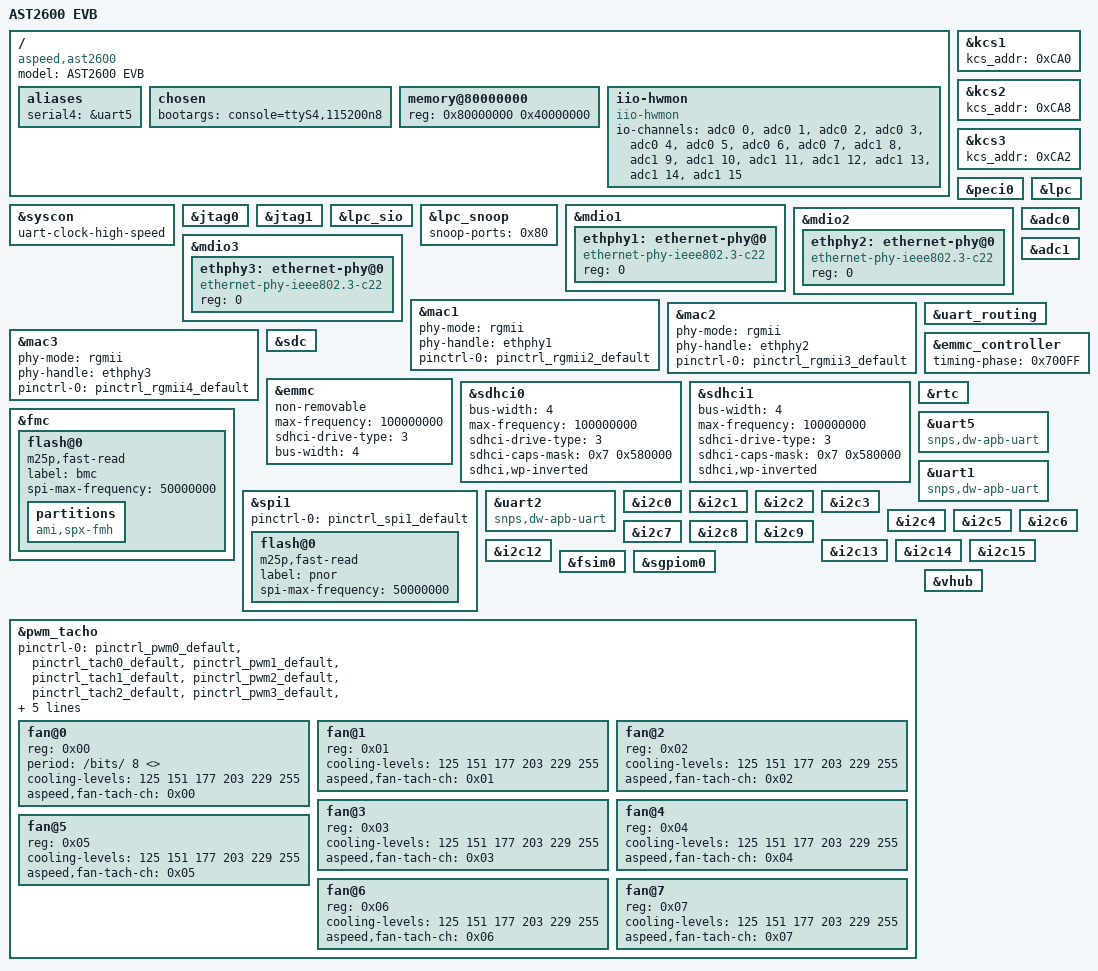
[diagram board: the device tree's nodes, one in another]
// SPDX-License-Identifier: GPL-2.0-or-later
// Copyright 2019 IBM Corp.

/dts-v1/;

#include "aspeed-g6.dtsi"
#include <dt-bindings/gpio/aspeed-gpio.h>
#include <dt-bindings/i2c/i2c.h>

/ {
	model = "AST2600 EVB";
	compatible = "aspeed,ast2600";

	aliases {
		serial4 = &uart5;
	};

	chosen {
		bootargs = "console=ttyS4,115200n8";
	};

	memory@80000000 {
		device_type = "memory";
		reg = <0x80000000 0x40000000>;
	};

    iio-hwmon {
        compatible = "iio-hwmon";
        io-channels = <&adc0 0>, <&adc0 1>, <&adc0 2>, <&adc0 3>,
                        <&adc0 4>, <&adc0 5>, <&adc0 6>, <&adc0 7>,
                        <&adc1 8>, <&adc1 9>, <&adc1 10>, <&adc1 11>,
                        <&adc1 12>, <&adc1 13>, <&adc1 14>, <&adc1 15>;
    };

};

&syscon {
        uart-clock-high-speed;
        status = "okay";
};

&kcs1 {
        kcs_addr = <0xCA0>;
        status = "okay";
};

&kcs2 {
        kcs_addr = <0xCA8>;
        status = "okay";
};

&kcs3 {
        kcs_addr = <0xCA2>;
        status = "okay";
};

&peci0 {
    status = "okay";
};

&lpc {
    status = "okay";
};

&jtag0 {
        status = "okay";
};

&jtag1 {
        status = "okay";
};

&lpc_sio {
        status = "okay";
};

&lpc_snoop {
        snoop-ports = <0x80>;
        status = "okay";
};

&mdio1 {
	status = "okay";

	ethphy1: ethernet-phy@0 {
		compatible = "ethernet-phy-ieee802.3-c22";
		reg = <0>;
	};
};

&mdio2 {
	status = "okay";

	ethphy2: ethernet-phy@0 {
		compatible = "ethernet-phy-ieee802.3-c22";
		reg = <0>;
	};
};

&mdio3 {
	status = "okay";

	ethphy3: ethernet-phy@0 {
		compatible = "ethernet-phy-ieee802.3-c22";
		reg = <0>;
	};
};

&mac1 {
	status = "okay";

	phy-mode = "rgmii";
	phy-handle = <&ethphy1>;

	pinctrl-names = "default";
	pinctrl-0 = <&pinctrl_rgmii2_default>;
};

&mac2 {
	status = "okay";

	phy-mode = "rgmii";
	phy-handle = <&ethphy2>;

	pinctrl-names = "default";
	pinctrl-0 = <&pinctrl_rgmii3_default>;
};

&mac3 {
	status = "okay";

	phy-mode = "rgmii";
	phy-handle = <&ethphy3>;

	pinctrl-names = "default";
	pinctrl-0 = <&pinctrl_rgmii4_default>;
};

&adc0 {
        status = "okay";
};

&adc1 {
        status = "okay";
};

&uart_routing {
        status = "okay";
};

&sdc {
	status = "okay";	
};

&emmc_controller {
	status = "okay";
	timing-phase = <0x700FF>;
};

&emmc {
    status = "okay";
    non-removable;
    max-frequency = <100000000>;
    sdhci-drive-type = /bits/ 8 <3>;
#if 1
    bus-width = <4>;
#else
    bus-width = <8>;
    pinctrl-0 = <&pinctrl_emmc_default
            &pinctrl_emmcg8_default>;
#endif

};

&sdhci0 {
    status = "okay";
    bus-width = <4>;
    max-frequency = <100000000>;
    sdhci-drive-type = /bits/ 8 <3>;
    /* SDR104/DDR50/SDR50 bits in CAPA2 is not supported */
    sdhci-caps-mask = <0x7 0x580000>;
    sdhci,wp-inverted;
};

&sdhci1 {
    status = "okay";
    bus-width = <4>;
    max-frequency = <100000000>;
    sdhci-drive-type = /bits/ 8 <3>;
    sdhci-caps-mask = <0x7 0x580000>;
    sdhci,wp-inverted;
};

&rtc {
	status = "okay";
};

&fmc {
	status = "okay";
	flash@0 {
		status = "okay";
		m25p,fast-read;
		label = "bmc";
		spi-max-frequency = <50000000>;
        partitions {
            compatible = "ami,spx-fmh";
        };
	};
};

&spi1 {
	status = "okay";
	pinctrl-names = "default";
	pinctrl-0 = <&pinctrl_spi1_default>;

	flash@0 {
		status = "okay";
		m25p,fast-read;
		label = "pnor";
		spi-max-frequency = <50000000>;
	};
};

&uart5 {
	// Workaround for A0
	compatible = "snps,dw-apb-uart";
};

&uart1 {
	// Workaround for A0
	compatible = "snps,dw-apb-uart";
	status = "okay";
};

&uart2 {
	// Workaround for A0
	compatible = "snps,dw-apb-uart";
	status = "okay";
};

&i2c0 {
	status = "okay";
};

&i2c1 {
	status = "okay";
};

&i2c2 {
	status = "okay";
};

&i2c3 {
	status = "okay";
};

&i2c4 {
	status = "okay";
};

&i2c5 {
	status = "okay";
};

&i2c6 {
	status = "okay";
};

&i2c7 {
	status = "okay";
};

&i2c8 {
	status = "okay";
};

&i2c9 {
	status = "okay";
};

&i2c12 {
	status = "okay";
};

&i2c13 {
	status = "okay";
};

&i2c14 {
	status = "okay";
};

&i2c15 {
	status = "okay";
};

&fsim0 {
	status = "okay";
};
&sgpiom0 {
        status = "okay";
};

&pwm_tacho {
        status = "okay";
        pinctrl-names = "default";
        pinctrl-0 = <&pinctrl_pwm0_default &pinctrl_tach0_default
                        &pinctrl_pwm1_default &pinctrl_tach1_default
                        &pinctrl_pwm2_default &pinctrl_tach2_default
                        &pinctrl_pwm3_default &pinctrl_tach3_default
                        &pinctrl_pwm4_default &pinctrl_tach4_default
                        &pinctrl_pwm5_default &pinctrl_tach5_default
                        &pinctrl_pwm6_default &pinctrl_tach6_default
                        &pinctrl_pwm7_default &pinctrl_tach7_default>;

        fan@0 {
                reg = <0x00>;
                period = /bits/ 8 <>;
                cooling-levels = /bits/ 8 <125 151 177 203 229 255>;
                aspeed,fan-tach-ch = /bits/ 8 <0x00>;
        };

        fan@1 {
                reg = <0x01>;
                cooling-levels = /bits/ 8 <125 151 177 203 229 255>;
                aspeed,fan-tach-ch = /bits/ 8 <0x01>;
        };

        fan@2 {
                reg = <0x02>;
                cooling-levels = /bits/ 8 <125 151 177 203 229 255>;
                aspeed,fan-tach-ch = /bits/ 8 <0x02>;
        };

        fan@3 {
                reg = <0x03>;
                cooling-levels = /bits/ 8 <125 151 177 203 229 255>;
                aspeed,fan-tach-ch = /bits/ 8 <0x03>;
        };

        fan@4 {
                reg = <0x04>;
                cooling-levels = /bits/ 8 <125 151 177 203 229 255>;
                aspeed,fan-tach-ch = /bits/ 8 <0x04>;
        };

        fan@5 {
                reg = <0x05>;
                cooling-levels = /bits/ 8 <125 151 177 203 229 255>;
                aspeed,fan-tach-ch = /bits/ 8 <0x05>;
        };

        fan@6 {
                reg = <0x06>;
                cooling-levels = /bits/ 8 <125 151 177 203 229 255>;
                aspeed,fan-tach-ch = /bits/ 8 <0x06>;
        };

        fan@7 {
                reg = <0x07>;
                cooling-levels = /bits/ 8 <125 151 177 203 229 255>;
                aspeed,fan-tach-ch = /bits/ 8 <0x07>;
        };

   
};

&vhub {
        status = "okay";
};

#include "legacy.dtsi" /* For Legacy AMI Drivers */

